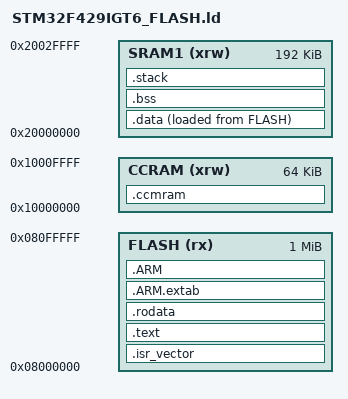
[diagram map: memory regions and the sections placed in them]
/**
 * @file STM32F429IGT6_FLASH.ld
 * @brief Linker script for STM32F429IGT6
 */

MEMORY
{
    FLASH (rx)  : ORIGIN = 0x08000000, LENGTH = 1024K
    SRAM1 (xrw) : ORIGIN = 0x20000000, LENGTH = 192K
    CCRAM (xrw) : ORIGIN = 0x10000000, LENGTH = 64K
}

_Min_Stack_Size = 0x400;
ENTRY(Reset_Handler)

SECTIONS
{
    .isr_vector :
    {
        . = ALIGN(4);
        KEEP(*(.isr_vector))
        . = ALIGN(4);
    } > FLASH

    .text :
    {
        . = ALIGN(4);
        *(.text)
        *(.text*)
        *(.glue_7)
        *(.glue_7t)
        *(.eh_frame)
        KEEP (*(.init))
        KEEP (*(.fini))
        . = ALIGN(4);
        _etext = .;
    } > FLASH

    .rodata :
    {
        . = ALIGN(4);
        *(.rodata)
        *(.rodata*)
        . = ALIGN(4);
    } > FLASH

    .ARM.extab :
    {
        *(.ARM.extab* .gnu.linkonce.armextab.*)
    } > FLASH
    
    .ARM :
    {
        __exidx_start = .;
        *(.ARM.exidx*)
        __exidx_end = .;
    } > FLASH

    _sidata = LOADADDR(.data);
    
    .data :
    {
        . = ALIGN(4);
        _sdata = .;
        *(.data)
        *(.data*)
        . = ALIGN(4);
        _edata = .;
    } > SRAM1 AT > FLASH

    .bss :
    {
        . = ALIGN(4);
        _sbss = .;
        *(.bss)
        *(.bss*)
        *(COMMON)
        . = ALIGN(4);
        _ebss = .;
    } > SRAM1

    .ccmram (NOLOAD) :
    {
        . = ALIGN(4);
        _sccmram = .;
        *(.ccmram)
        *(.ccmram*)
        . = ALIGN(4);
        _eccmram = .;
    } > CCRAM

    .stack (NOLOAD) :
    {
        . = ALIGN(8);
        . = . + _Min_Stack_Size;
        . = ALIGN(8);
        _estack = .;
    } > SRAM1

    .ARM.attributes 0 : { *(.ARM.attributes) }
}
